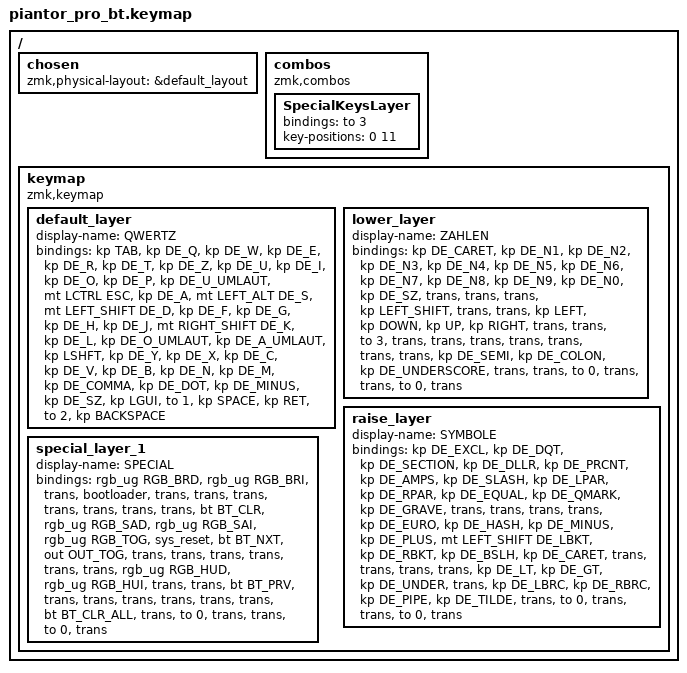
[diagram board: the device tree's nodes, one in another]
/*
 * Copyright (c) 2020 The ZMK Contributors
 *
 * SPDX-License-Identifier: MIT
 */

#include "keys_de.h"
#include <behaviors.dtsi>
#include <dt-bindings/zmk/bt.h>
#include <dt-bindings/zmk/keys.h>
#include <dt-bindings/zmk/outputs.h>
#include <dt-bindings/zmk/rgb.h>

/ {
    chosen { zmk,physical-layout = &default_layout; };
};

/ {
    combos {
        compatible = "zmk,combos";

        SpecialKeysLayer {
            bindings = <&to 3>;
            key-positions = <0 11>;
        };
    };

    keymap {
        compatible = "zmk,keymap";

        default_layer {
            display-name = "QWERTZ";

            // -----------------------------------------------------------------------------------------
            // |  TAB |  Q  |  W  |  E  |  R  |  T  |  Z  |  U  |  I  |  O  |  P  |  Ü  |
            // | CTRL |  A  |  S  |  D  |  F  |  G  |  H  |  J  |  K  |  L  |  Ö  |  Ä  |
            // | SHFT |  Y  |  X  |  C  |  V  |  B  |  N  |  M  |  ,  |  .  |  -  |  ß  |
            //                     | GUI | LWR | SPC | ENT | RSE | BSPC |
            //
            // Home-Row-Mods: halten = CTRL (ESC-Tap), ALT (S), SHIFT (D und K)

            bindings = <
&kp TAB  &kp DE_Q  &kp DE_W  &kp DE_E  &kp DE_R  &kp DE_T  &kp DE_Z  &kp DE_U  &kp DE_I  &kp DE_O  &kp DE_P  &kp DE_U_UMLAUT  &mt LCTRL ESC  &kp DE_A  &mt LEFT_ALT DE_S  &mt LEFT_SHIFT DE_D  &kp DE_F  &kp DE_G  &kp DE_H  &kp DE_J  &mt RIGHT_SHIFT DE_K  &kp DE_L  &kp DE_O_UMLAUT  &kp DE_A_UMLAUT  &kp LSHFT  &kp DE_Y  &kp DE_X  &kp DE_C  &kp DE_V  &kp DE_B  &kp DE_N  &kp DE_M  &kp DE_COMMA  &kp DE_DOT  &kp DE_MINUS  &kp DE_SZ  &kp LGUI  &to 1  &kp SPACE  &kp RET  &to 2  &kp BACKSPACE
            >;
        };

        lower_layer {
            display-name = "ZAHLEN";

            // -----------------------------------------------------------------------------------------
            // Exakt die deutsche Zahlenreihe:
            // |  1  |  2  |  3  |  4  |  5  |  6  |  7  |  8  |  9  |  0  |  ß  |  ´  |
            // | EXIT|  a  |  s  | SHFT|  f  |  g  |  ←  |  ↓  |  ↑  |  →  |  ö  |  ä  |
            // | LOCK| RGB |  x  |  c  |  v  |  b  |  n  |  m  |  ;  |  :  |  -  |  ß  |
            //                     | GUI |     | SPC | ENT |     | BSPC |

            bindings = <
&kp DE_CARET  &kp DE_N1  &kp DE_N2  &kp DE_N3  &kp DE_N4  &kp DE_N5  &kp DE_N6  &kp DE_N7  &kp DE_N8  &kp DE_N9  &kp DE_N0  &kp DE_SZ  &trans  &trans  &trans  &kp LEFT_SHIFT  &trans  &trans  &kp LEFT  &kp DOWN  &kp UP  &kp RIGHT  &trans  &trans  &to 3  &trans  &trans  &trans  &trans  &trans  &trans  &trans  &kp DE_SEMI  &kp DE_COLON  &kp DE_UNDERSCORE  &trans  &trans  &to 0  &trans  &trans  &to 0  &trans
            >;
        };

        raise_layer {
            display-name = "SYMBOLE";

            // -----------------------------------------------------------------------------------------
            // Exakt die deutsche Shift-Reihe plus Sonderzeichen:
            // |  !  |  "  |  §  |  $  |  %  |  &  |  /  |  (  |  )  |  =  |  ?  |  `  |
            // | EXIT|  ü  |  ä  |  ö  |  €  |  #  |  -  |  +  |  [  |  ]  |  \  |  ^  |
            // | LOCK|  y  |  x  |  c  |  <  |  >  |  _  |  +  |  {  |  }  |  |  |  ~  |
            //                     | GUI |     | SPC | ENT |     | BSPC |

            bindings = <
&kp DE_EXCL  &kp DE_DQT  &kp DE_SECTION  &kp DE_DLLR  &kp DE_PRCNT  &kp DE_AMPS  &kp DE_SLASH  &kp DE_LPAR  &kp DE_RPAR  &kp DE_EQUAL  &kp DE_QMARK  &kp DE_GRAVE  &trans  &trans  &trans  &trans  &kp DE_EURO  &kp DE_HASH  &kp DE_MINUS  &kp DE_PLUS  &mt LEFT_SHIFT DE_LBKT  &kp DE_RBKT  &kp DE_BSLH  &kp DE_CARET  &trans  &trans  &trans  &trans  &kp DE_LT  &kp DE_GT  &kp DE_UNDER  &trans  &kp DE_LBRC  &kp DE_RBRC  &kp DE_PIPE  &kp DE_TILDE  &trans  &to 0  &trans  &trans  &to 0  &trans
            >;
        };

        special_layer_1 {
            display-name = "SPECIAL";
            bindings = <
&rgb_ug RGB_BRD  &rgb_ug RGB_BRI  &trans  &bootloader  &trans  &trans  &trans  &trans  &trans  &trans  &trans  &bt BT_CLR  &rgb_ug RGB_SAD  &rgb_ug RGB_SAI  &rgb_ug RGB_TOG  &sys_reset  &bt BT_NXT  &out OUT_TOG  &trans  &trans  &trans  &trans  &trans  &trans  &rgb_ug RGB_HUD  &rgb_ug RGB_HUI  &trans  &trans  &bt BT_PRV  &trans  &trans  &trans  &trans  &trans  &trans  &bt BT_CLR_ALL  &trans  &to 0  &trans  &trans  &to 0  &trans
            >;
        };
    };
};
